# STM32G081 register map
File version: 1.8
CPU: CM0 r0p1, little endian, MPU, no FPU, 2 interrupt priority bits
Registers are 32-bit, read-write, reset 0x0 unless marked. A register's access mark holds for its fields unless they carry their own. Offsets are from the block's base; [hi:lo] are bit positions; {n}, {i} and the like mark numbered series; 'fields as' and 'values as' point back to an identical list.

## EXTI — External interrupt/event controller
Base 0x40021800
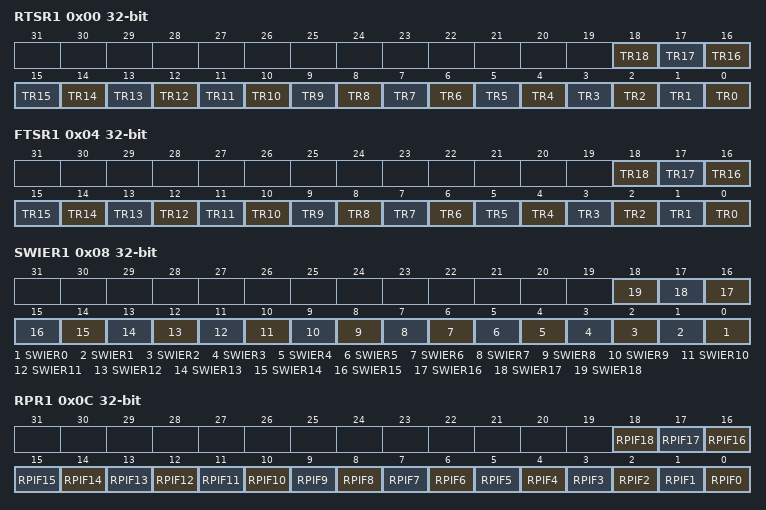
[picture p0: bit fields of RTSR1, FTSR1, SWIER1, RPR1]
0x00 RTSR1 — EXTI rising trigger selection register
  [all] fields
    0=Disabled (Rising edge trigger is disabled); 1=Enabled (Rising edge trigger is enabled)
  [n] TR{n} (n=0..18) — Rising trigger event configuration bit of Configurable Event input
0x04 FTSR1 — EXTI falling trigger selection register
  [all] fields
    0=Disabled (Falling edge trigger is disabled); 1=Enabled (Falling edge trigger is enabled)
  [n] TR{n} (n=0..18) — Rising trigger event configuration bit of Configurable Event input
0x08 SWIER1 — EXTI software interrupt event register
  [all] fields
    on write: 1=Pend (Generates an interrupt request)
  [n] SWIER{n} (n=0..18) — Rising trigger event configuration bit of Configurable Event input
0x0C RPR1 — EXTI rising edge pending register
  [all] fields
    on read: 0=NotPending (No trigger request occurred); 1=Pending (Selected trigger request occurred) | on write: 1=Clears pending bit
  [n] RPIF{n} write-1-clears (n=6..18) — configurable event inputs x rising edge Pending bit.
  [5] RPIF5 write-1-clears — configurable event inputs x rising edge Pending bit
  [n] RPIF{n} write-1-clears (n=0..4) — configurable event inputs x rising edge Pending bit.
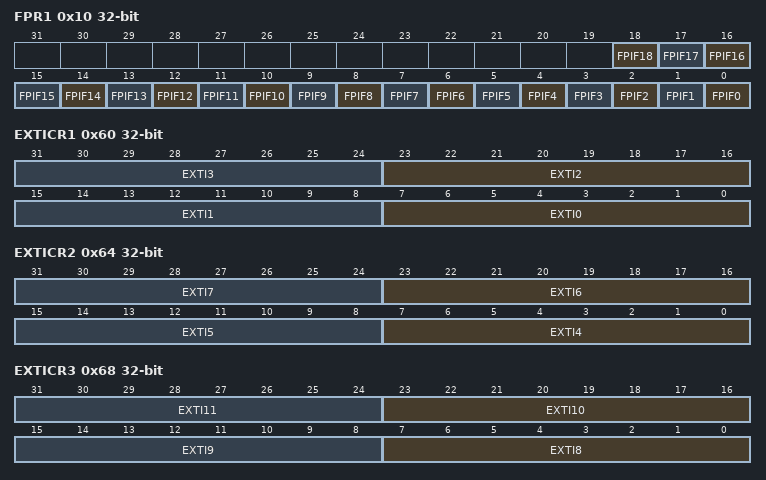
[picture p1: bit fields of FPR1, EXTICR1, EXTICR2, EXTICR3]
0x10 FPR1 — EXTI falling edge pending register
  [all] fields
    values as the fields of RPR1
  [n] FPIF{n} write-1-clears (n=0..18) — configurable event inputs x falling edge pending bit.
0x60 EXTICR1 — EXTI external interrupt selection register
  [all] fields
    0=PA (Select PAx as the source input for the EXTIx external interrupt); 1=PB (Select PBx as the source input for the EXTIx external interrupt); 2=PC (Select PCx as the source input for the EXTIx external interrupt); 3=PD (Select PDx as the source input for the EXTIx external interrupt); 5=PF (Select PFx as the source input for the EXTIx external interrupt)
  [8n+7:8n] EXTI{n} (n=0..3) — GPIO port selection
0x64 EXTICR2 — EXTI external interrupt selection register
  [all] fields
    values as the fields of EXTICR1
  [8n-25:8n-32] EXTI{n} (n=4..7) — GPIO port selection
0x68 EXTICR3 — EXTI external interrupt selection register
  [all] fields
    values as the fields of EXTICR1
  [8n-57:8n-64] EXTI{n} (n=8..11) — GPIO port selection
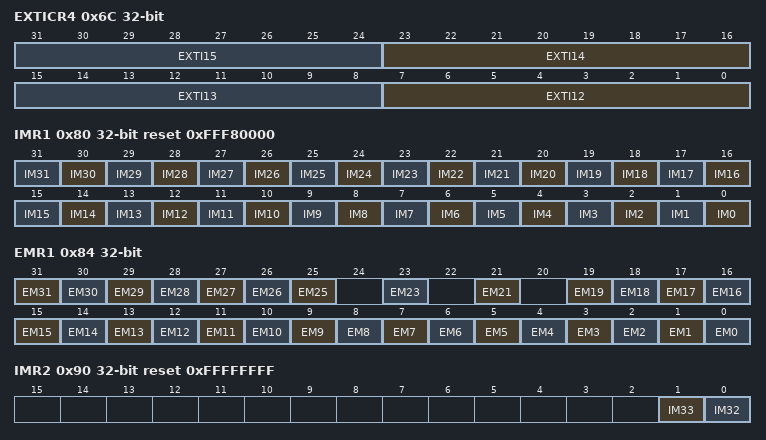
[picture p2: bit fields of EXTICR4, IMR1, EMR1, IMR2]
0x6C EXTICR4 — EXTI external interrupt selection register
  [all] fields
    values as the fields of EXTICR1
  [8n-89:8n-96] EXTI{n} (n=12..15) — GPIO port selection
0x80 IMR1 reset 0xFFF80000 — EXTI CPU wakeup with interrupt mask register
  [all] fields
    0=Masked (Interrupt request line is masked); 1=Unmasked (Interrupt request line is unmasked)
  [n] IM{n} (n=0..31) — CPU wakeup with interrupt mask on event input
0x84 EMR1 (alternate view of IMR1) — EXTI CPU wakeup with event mask register
  [all] fields
    0=Masked (Event request line is masked); 1=Unmasked (Event request line is unmasked)
  [n] EM{n} (n=25..31) — CPU wakeup with event mask on event input
  [23] EM23 — CPU wakeup with event mask on event input
  [21] EM21 — CPU wakeup with event mask on event input
  [n] EM{n} (n=0..19) — CPU wakeup with event mask on event input
0x90 IMR2 reset 0xFFFFFFFF — EXTI CPU wakeup with interrupt mask register
  [1] IM33 — CPU wakeup with interrupt mask on event input
    values as the fields of IMR1
  [0] IM32 — CPU wakeup with interrupt mask on event input
    values as the fields of IMR1
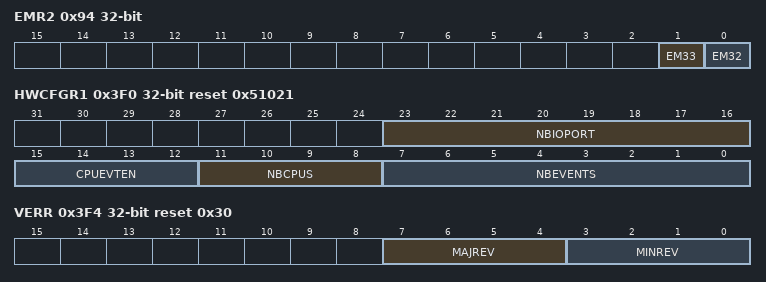
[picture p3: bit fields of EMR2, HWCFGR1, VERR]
0x94 EMR2 — EXTI CPU wakeup with event mask register
  [1] EM33 — CPU wakeup with event mask on event input
    values as the fields of EMR1
  [0] EM32 — CPU wakeup with event mask on event input
    values as the fields of EMR1
0x3D8 HWCFGR7 — Hardware configuration registers
  [31:0] CPUEVENT — HW configuration CPU event generation
0x3DC HWCFGR6 reset 0x3 — Hardware configuration registers
  [31:0] CPUEVENT — HW configuration CPU event generation
0x3E0 HWCFGR5 reset 0xFEAFFFFF — Hardware configuration registers
  [31:0] CPUEVENT — HW configuration CPU event generation
0x3E4 HWCFGR4 — Hardware configuration registers
  [31:0] EVENT_TRG — HW configuration event trigger type
0x3E8 HWCFGR3 — Hardware configuration registers
  [31:0] EVENT_TRG — HW configuration event trigger type
0x3EC HWCFGR2 reset 0x7FFFF — Hardware configuration registers
  [31:0] EVENT_TRG — HW configuration event trigger type
0x3F0 HWCFGR1 ro reset 0x51021 — Hardware configuration registers
  [23:16] NBIOPORT — HW configuration of number of IO ports
  [15:12] CPUEVTEN — HW configuration of CPU event output enable
  [11:8] NBCPUS — configuration number of CPUs
  [7:0] NBEVENTS — configuration number of event
0x3F4 VERR ro reset 0x30 — AES version register
  [7:4] MAJREV — Major revision
  [3:0] MINREV — Minor revision
0x3F8 IPIDR ro reset 0xE0001 — AES identification register
  [31:0] ID — Identification code
0x3FC SIDR ro reset 0xA3C5DD01 — AES size ID register
  [31:0] ID — Size Identification code
